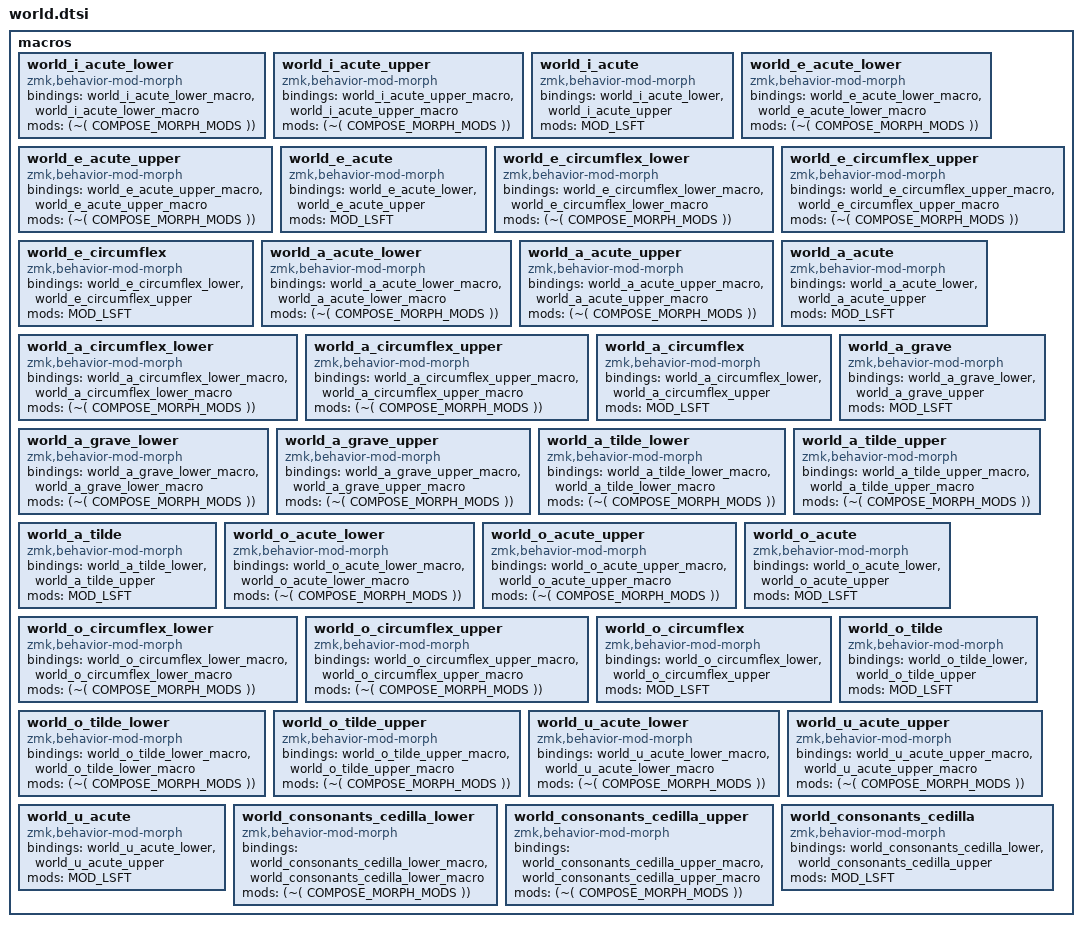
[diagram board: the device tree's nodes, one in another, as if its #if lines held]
macros {

    //////////////////////////////////////////////////////////////////////////
    //
    // World layer - international characters
    //
    //////////////////////////////////////////////////////////////////////////

    //
    // WORLD_USE_COMPOSE uses OS-native Compose keycodes instead of Unicode
    // for characters in the "localizing" section of the `world.yaml` file.
    //
    //#define WORLD_USE_COMPOSE

    //
    // UNICODE_TAP_DELAY defines how long the macro waits (milliseconds)
    // between keystrokes while inputting the Unicode codepoint shortcut.
    //
    #ifndef UNICODE_TAP_DELAY
    #define UNICODE_TAP_DELAY 1
    #endif

    //
    // UNICODE_SEQ_DELAY defines how long the macro waits (milliseconds)
    // between emitting Unicode codepoints in multi-codepoint characters.
    //
    #ifndef UNICODE_SEQ_DELAY
    #define UNICODE_SEQ_DELAY 10
    #endif

    #define UNICODE(name, ...) \
        ZMK_MACRO(name, \
            wait-ms = <UNICODE_TAP_DELAY>; \
            tap-ms = <UNICODE_TAP_DELAY>; \
            bindings = __VA_ARGS__; \
        )

    //
    // UNICODE_SEQ_LINUX() specifies how Unicode hexadecimal codepoint
    // keystrokes are transformed into Unicode characters under Linux.
    //
    #ifndef UNICODE_SEQ_LINUX
    #define UNICODE_SEQ_LINUX(keystrokes) \
        <&macro_tap &kp LC(LS(U)) keystrokes &kp ENTER>
    #endif

    //
    // UNICODE_SEQ_MACOS() specifies how Unicode hexadecimal codepoint
    // keystrokes are transformed into Unicode characters under macOS.
    //
    #ifndef UNICODE_SEQ_MACOS
    #define UNICODE_SEQ_MACOS(keystrokes) \
        <&macro_press &kp LALT> ,\
        <&macro_tap keystrokes> ,\
        <&macro_release &kp LALT>
    #endif

    //
    // UNICODE_SEQ_WINDOWS() specifies how Unicode hexadecimal codepoint
    // keystrokes are transformed into Unicode characters under Windows.
    //
    // If you've configured WinCompose to use a different trigger hotkey,
    // such as F13 instead of the default RA(U) shortcut, simply override
    // this definition to adapt all UNICODE() function calls accordingly.
    //
    #ifndef UNICODE_SEQ_WINDOWS
    #define UNICODE_SEQ_WINDOWS(keystrokes) \
        <&macro_tap &kp RALT &kp U keystrokes &kp ENTER>
    #endif

    //
    // COMPOSE_KEY_LINUX specifies the keycode for Compose key in Linux,
    // which may be RALT by default but can be reconfigured as follows:
    //
    // $ setxkbmap -option compose:sclk # use ScrollLock as Compose key
    //
    // See xkeyboard-config(7) for possible choices for the Compose key:
    // https://manpages.debian.org/stable/xkb-data/xkeyboard-config.7.en.html#Position_of_Compose_key
    //
    // #define COMPOSE_KEY_LINUX RALT            // compose:ralt
    // #define COMPOSE_KEY_LINUX LGUI            // compose:lwin
    // #define COMPOSE_KEY_LINUX RA(LGUI)        // compose:lwin-altgr
    // #define COMPOSE_KEY_LINUX RGUI            // compose:rwin
    // #define COMPOSE_KEY_LINUX RA(RGUI)        // compose:rwin-altgr
    // #define COMPOSE_KEY_LINUX K_MENU          // compose:menu
    // #define COMPOSE_KEY_LINUX RA(K_MENU)      // compose:menu-altgr
    // #define COMPOSE_KEY_LINUX LCTL            // compose:lctrl
    // #define COMPOSE_KEY_LINUX RA(LCTL)        // compose:lctrl-altgr
    // #define COMPOSE_KEY_LINUX RCTL            // compose:rctrl
    // #define COMPOSE_KEY_LINUX RA(RCTL)        // compose:rctrl-altgr
    // #define COMPOSE_KEY_LINUX CAPS            // compose:caps
    // #define COMPOSE_KEY_LINUX RA(CAPS)        // compose:caps-altgr
    // #define COMPOSE_KEY_LINUX NON_US_BSLH     // compose:102
    // #define COMPOSE_KEY_LINUX RA(NON_US_BSLH) // compose:102-altgr
    // #define COMPOSE_KEY_LINUX PAUSE_BREAK     // compose:paus
    // #define COMPOSE_KEY_LINUX PSCRN           // compose:prsc
    // #define COMPOSE_KEY_LINUX SLCK            // compose:sclk
    //
    #ifndef COMPOSE_KEY_LINUX
    #define COMPOSE_KEY_LINUX RALT
    #endif

    //
    // COMPOSE_SEQ_LINUX() prefixes keystrokes with the Linux Compose key.
    //
    #ifndef COMPOSE_SEQ_LINUX
    #define COMPOSE_SEQ_LINUX(keystrokes) \
        <&macro_tap &kp COMPOSE_KEY_LINUX keystrokes>
    #endif

    //
    // COMPOSE_SEQ_MACOS() formats keystrokes for macOS character entry.
    //
    #ifndef COMPOSE_SEQ_MACOS
    #define COMPOSE_SEQ_MACOS(keystrokes) \
        <&macro_tap keystrokes>
    #endif

    //
    // COMPOSE_SEQ_WINDOWS() wraps keystrokes in Windows AltCode sequence.
    //
    #ifndef COMPOSE_SEQ_WINDOWS
    #define COMPOSE_SEQ_WINDOWS(keystrokes) \
        <&macro_press &kp LALT>, \
        <&macro_tap keystrokes>, \
        <&macro_release &kp LALT>
    #endif
    #if OPERATING_SYSTEM == 'L'
        #define UNICODE_MORPH_MODS (MOD_LCTL|MOD_LSFT)
    #elif OPERATING_SYSTEM == 'M'
        #define UNICODE_MORPH_MODS MOD_LALT
    #elif OPERATING_SYSTEM == 'W'
        #define UNICODE_MORPH_MODS MOD_RALT
    #endif
    #if OPERATING_SYSTEM == 'L'
        // $ grep "compose:" /usr/share/X11/xkb/rules/base.lst
        // compose:ralt         Right Alt
        #if COMPOSE_KEY_LINUX == RALT
            #define COMPOSE_MORPH_MODS MOD_RALT
        // compose:lwin         Left Win
        #elif COMPOSE_KEY_LINUX == LGUI
            #define COMPOSE_MORPH_MODS MOD_LGUI
        // compose:lwin-altgr   3rd level of Left Win
        #elif COMPOSE_KEY_LINUX == RA(LGUI)
            #define COMPOSE_MORPH_MODS (MOD_LGUI|MOD_RALT)
        // compose:rwin         Right Win
        #elif COMPOSE_KEY_LINUX == RGUI
            #define COMPOSE_MORPH_MODS MOD_RGUI
        // compose:rwin-altgr   3rd level of Right Win
        #elif COMPOSE_KEY_LINUX == RA(RGUI)
            #define COMPOSE_MORPH_MODS (MOD_RGUI|MOD_RALT)
        // compose:menu         Menu
        // compose:menu-altgr   3rd level of Menu
        #elif COMPOSE_KEY_LINUX == RA(K_MENU)
            #define COMPOSE_MORPH_MODS MOD_RALT
        // compose:lctrl        Left Ctrl
        #elif COMPOSE_KEY_LINUX == LCTL
            #define COMPOSE_MORPH_MODS MOD_LCTL
        // compose:lctrl-altgr  3rd level of Left Ctrl
        #elif COMPOSE_KEY_LINUX == RA(LCTL)
            #define COMPOSE_MORPH_MODS (MOD_LCTL|MOD_RALT)
        // compose:rctrl        Right Ctrl
        #elif COMPOSE_KEY_LINUX == RCTL
            #define COMPOSE_MORPH_MODS MOD_RCTL
        // compose:rctrl-altgr  3rd level of Right Ctrl
        #elif COMPOSE_KEY_LINUX == RA(RCTL)
            #define COMPOSE_MORPH_MODS (MOD_RCTL|MOD_RALT)
        // compose:caps         Caps Lock
        // compose:caps-altgr   3rd level of Caps Lock
        #elif COMPOSE_KEY_LINUX == RA(CAPS)
            #define COMPOSE_MORPH_MODS MOD_RALT
        // compose:102          The "&lt; &gt;" key
        // compose:102-altgr    3rd level of the "&lt; &gt;" key
        #elif COMPOSE_KEY_LINUX == RA(NON_US_BSLH)
            #define COMPOSE_MORPH_MODS MOD_RALT
        // compose:paus         Pause
        // compose:prsc         PrtSc
        // compose:sclk         Scroll Lock
        #else
            #define COMPOSE_MORPH_MODS 0
        #endif
    #elif OPERATING_SYSTEM == 'M'
        #define COMPOSE_MORPH_MODS 0
    #elif OPERATING_SYSTEM == 'W'
        #define COMPOSE_MORPH_MODS MOD_LALT
    #endif


    //
    // characters
    //
    UNICODE(world_i_acute_lower_macro, /* í */
      #if OPERATING_SYSTEM == 'L'
        #ifdef WORLD_USE_COMPOSE
        #define WORLD_USE_COMPOSE_FOR_world_i_acute_lower
        COMPOSE_SEQ_LINUX(&kp SQT &kp I)
        #else
        UNICODE_SEQ_LINUX(&kp E &kp D)
        #endif
      #elif OPERATING_SYSTEM == 'M'
        #ifdef WORLD_USE_COMPOSE
        #define WORLD_USE_COMPOSE_FOR_world_i_acute_lower
        COMPOSE_SEQ_MACOS(&kp LA(E) &kp I)
        #else
        UNICODE_SEQ_MACOS(&kp N0 &kp N0 &kp E &kp D)
        #endif
      #elif OPERATING_SYSTEM == 'W'
        #ifdef WORLD_USE_COMPOSE
        #define WORLD_USE_COMPOSE_FOR_world_i_acute_lower
        COMPOSE_SEQ_WINDOWS(&kp KP_N0 &kp KP_N2 &kp KP_N3 &kp KP_N7)
        #else
        UNICODE_SEQ_WINDOWS(&kp N0 &kp E &kp D)
        #endif
      #endif
    )
    world_i_acute_lower: world_i_acute_lower {
        compatible = "zmk,behavior-mod-morph";
        #binding-cells = <0>;
        bindings = <&world_i_acute_lower_macro>, <&world_i_acute_lower_macro>;
        mods = <(~(
#ifdef WORLD_USE_COMPOSE_FOR_world_i_acute_lower
COMPOSE_MORPH_MODS
#else
UNICODE_MORPH_MODS
#endif
))>;
    };
    UNICODE(world_i_acute_upper_macro, /* Í */
      #if OPERATING_SYSTEM == 'L'
        #ifdef WORLD_USE_COMPOSE
        #define WORLD_USE_COMPOSE_FOR_world_i_acute_upper
        COMPOSE_SEQ_LINUX(&kp SQT &kp LS(I))
        #else
        UNICODE_SEQ_LINUX(&kp C &kp D)
        #endif
      #elif OPERATING_SYSTEM == 'M'
        #ifdef WORLD_USE_COMPOSE
        #define WORLD_USE_COMPOSE_FOR_world_i_acute_upper
        COMPOSE_SEQ_MACOS(&kp LA(E) &kp LS(I))
        #else
        UNICODE_SEQ_MACOS(&kp N0 &kp N0 &kp C &kp D)
        #endif
      #elif OPERATING_SYSTEM == 'W'
        #ifdef WORLD_USE_COMPOSE
        #define WORLD_USE_COMPOSE_FOR_world_i_acute_upper
        COMPOSE_SEQ_WINDOWS(&kp KP_N0 &kp KP_N2 &kp KP_N0 &kp KP_N5)
        #else
        UNICODE_SEQ_WINDOWS(&kp N0 &kp C &kp D)
        #endif
      #endif
    )
    world_i_acute_upper: world_i_acute_upper {
        compatible = "zmk,behavior-mod-morph";
        #binding-cells = <0>;
        bindings = <&world_i_acute_upper_macro>, <&world_i_acute_upper_macro>;
        mods = <(~(
#ifdef WORLD_USE_COMPOSE_FOR_world_i_acute_upper
COMPOSE_MORPH_MODS
#else
UNICODE_MORPH_MODS
#endif
))>;
    };
    world_i_acute: world_i_acute {
        compatible = "zmk,behavior-mod-morph";
        #binding-cells = <0>;
        bindings = <&world_i_acute_lower>, <&world_i_acute_upper>;
        mods = <MOD_LSFT>;
    };
    UNICODE(world_e_acute_lower_macro, /* é */
      #if OPERATING_SYSTEM == 'L'
        #ifdef WORLD_USE_COMPOSE
        #define WORLD_USE_COMPOSE_FOR_world_e_acute_lower
        COMPOSE_SEQ_LINUX(&kp SQT &kp E)
        #else
        UNICODE_SEQ_LINUX(&kp E &kp N9)
        #endif
      #elif OPERATING_SYSTEM == 'M'
        #ifdef WORLD_USE_COMPOSE
        #define WORLD_USE_COMPOSE_FOR_world_e_acute_lower
        COMPOSE_SEQ_MACOS(&kp LA(E) &kp E)
        #else
        UNICODE_SEQ_MACOS(&kp N0 &kp N0 &kp E &kp N9)
        #endif
      #elif OPERATING_SYSTEM == 'W'
        #ifdef WORLD_USE_COMPOSE
        #define WORLD_USE_COMPOSE_FOR_world_e_acute_lower
        COMPOSE_SEQ_WINDOWS(&kp KP_N0 &kp KP_N2 &kp KP_N3 &kp KP_N3)
        #else
        UNICODE_SEQ_WINDOWS(&kp N0 &kp E &kp N9)
        #endif
      #endif
    )
    world_e_acute_lower: world_e_acute_lower {
        compatible = "zmk,behavior-mod-morph";
        #binding-cells = <0>;
        bindings = <&world_e_acute_lower_macro>, <&world_e_acute_lower_macro>;
        mods = <(~(
#ifdef WORLD_USE_COMPOSE_FOR_world_e_acute_lower
COMPOSE_MORPH_MODS
#else
UNICODE_MORPH_MODS
#endif
))>;
    };
    UNICODE(world_e_acute_upper_macro, /* É */
      #if OPERATING_SYSTEM == 'L'
        #ifdef WORLD_USE_COMPOSE
        #define WORLD_USE_COMPOSE_FOR_world_e_acute_upper
        COMPOSE_SEQ_LINUX(&kp SQT &kp LS(E))
        #else
        UNICODE_SEQ_LINUX(&kp C &kp N9)
        #endif
      #elif OPERATING_SYSTEM == 'M'
        #ifdef WORLD_USE_COMPOSE
        #define WORLD_USE_COMPOSE_FOR_world_e_acute_upper
        COMPOSE_SEQ_MACOS(&kp LA(E) &kp LS(E))
        #else
        UNICODE_SEQ_MACOS(&kp N0 &kp N0 &kp C &kp N9)
        #endif
      #elif OPERATING_SYSTEM == 'W'
        #ifdef WORLD_USE_COMPOSE
        #define WORLD_USE_COMPOSE_FOR_world_e_acute_upper
        COMPOSE_SEQ_WINDOWS(&kp KP_N0 &kp KP_N2 &kp KP_N0 &kp KP_N1)
        #else
        UNICODE_SEQ_WINDOWS(&kp N0 &kp C &kp N9)
        #endif
      #endif
    )
    world_e_acute_upper: world_e_acute_upper {
        compatible = "zmk,behavior-mod-morph";
        #binding-cells = <0>;
        bindings = <&world_e_acute_upper_macro>, <&world_e_acute_upper_macro>;
        mods = <(~(
#ifdef WORLD_USE_COMPOSE_FOR_world_e_acute_upper
COMPOSE_MORPH_MODS
#else
UNICODE_MORPH_MODS
#endif
))>;
    };
    world_e_acute: world_e_acute {
        compatible = "zmk,behavior-mod-morph";
        #binding-cells = <0>;
        bindings = <&world_e_acute_lower>, <&world_e_acute_upper>;
        mods = <MOD_LSFT>;
    };
    UNICODE(world_e_circumflex_lower_macro, /* ê */
      #if OPERATING_SYSTEM == 'L'
        #ifdef WORLD_USE_COMPOSE
        #define WORLD_USE_COMPOSE_FOR_world_e_circumflex_lower
        COMPOSE_SEQ_LINUX(&kp CARET &kp E)
        #else
        UNICODE_SEQ_LINUX(&kp E &kp A)
        #endif
      #elif OPERATING_SYSTEM == 'M'
        #ifdef WORLD_USE_COMPOSE
        #define WORLD_USE_COMPOSE_FOR_world_e_circumflex_lower
        COMPOSE_SEQ_MACOS(&kp LA(I) &kp E)
        #else
        UNICODE_SEQ_MACOS(&kp N0 &kp N0 &kp E &kp A)
        #endif
      #elif OPERATING_SYSTEM == 'W'
        #ifdef WORLD_USE_COMPOSE
        #define WORLD_USE_COMPOSE_FOR_world_e_circumflex_lower
        COMPOSE_SEQ_WINDOWS(&kp KP_N0 &kp KP_N2 &kp KP_N3 &kp KP_N4)
        #else
        UNICODE_SEQ_WINDOWS(&kp N0 &kp E &kp A)
        #endif
      #endif
    )
    world_e_circumflex_lower: world_e_circumflex_lower {
        compatible = "zmk,behavior-mod-morph";
        #binding-cells = <0>;
        bindings = <&world_e_circumflex_lower_macro>, <&world_e_circumflex_lower_macro>;
        mods = <(~(
#ifdef WORLD_USE_COMPOSE_FOR_world_e_circumflex_lower
COMPOSE_MORPH_MODS
#else
UNICODE_MORPH_MODS
#endif
))>;
    };
    UNICODE(world_e_circumflex_upper_macro, /* Ê */
      #if OPERATING_SYSTEM == 'L'
        #ifdef WORLD_USE_COMPOSE
        #define WORLD_USE_COMPOSE_FOR_world_e_circumflex_upper
        COMPOSE_SEQ_LINUX(&kp CARET &kp LS(E))
        #else
        UNICODE_SEQ_LINUX(&kp C &kp A)
        #endif
      #elif OPERATING_SYSTEM == 'M'
        #ifdef WORLD_USE_COMPOSE
        #define WORLD_USE_COMPOSE_FOR_world_e_circumflex_upper
        COMPOSE_SEQ_MACOS(&kp LA(I) &kp LS(E))
        #else
        UNICODE_SEQ_MACOS(&kp N0 &kp N0 &kp C &kp A)
        #endif
      #elif OPERATING_SYSTEM == 'W'
        #ifdef WORLD_USE_COMPOSE
        #define WORLD_USE_COMPOSE_FOR_world_e_circumflex_upper
        COMPOSE_SEQ_WINDOWS(&kp KP_N0 &kp KP_N2 &kp KP_N0 &kp KP_N2)
        #else
        UNICODE_SEQ_WINDOWS(&kp N0 &kp C &kp A)
        #endif
      #endif
    )
    world_e_circumflex_upper: world_e_circumflex_upper {
        compatible = "zmk,behavior-mod-morph";
        #binding-cells = <0>;
        bindings = <&world_e_circumflex_upper_macro>, <&world_e_circumflex_upper_macro>;
        mods = <(~(
#ifdef WORLD_USE_COMPOSE_FOR_world_e_circumflex_upper
COMPOSE_MORPH_MODS
#else
UNICODE_MORPH_MODS
#endif
))>;
    };
    world_e_circumflex: world_e_circumflex {
        compatible = "zmk,behavior-mod-morph";
        #binding-cells = <0>;
        bindings = <&world_e_circumflex_lower>, <&world_e_circumflex_upper>;
        mods = <MOD_LSFT>;
    };
    UNICODE(world_a_acute_lower_macro, /* á */
      #if OPERATING_SYSTEM == 'L'
        #ifdef WORLD_USE_COMPOSE
        #define WORLD_USE_COMPOSE_FOR_world_a_acute_lower
        COMPOSE_SEQ_LINUX(&kp SQT &kp A)
        #else
        UNICODE_SEQ_LINUX(&kp E &kp N1)
        #endif
      #elif OPERATING_SYSTEM == 'M'
        #ifdef WORLD_USE_COMPOSE
        #define WORLD_USE_COMPOSE_FOR_world_a_acute_lower
        COMPOSE_SEQ_MACOS(&kp LA(E) &kp A)
        #else
        UNICODE_SEQ_MACOS(&kp N0 &kp N0 &kp E &kp N1)
        #endif
      #elif OPERATING_SYSTEM == 'W'
        #ifdef WORLD_USE_COMPOSE
        #define WORLD_USE_COMPOSE_FOR_world_a_acute_lower
        COMPOSE_SEQ_WINDOWS(&kp KP_N0 &kp KP_N2 &kp KP_N2 &kp KP_N5)
        #else
        UNICODE_SEQ_WINDOWS(&kp N0 &kp E &kp N1)
        #endif
      #endif
    )
    world_a_acute_lower: world_a_acute_lower {
        compatible = "zmk,behavior-mod-morph";
        #binding-cells = <0>;
        bindings = <&world_a_acute_lower_macro>, <&world_a_acute_lower_macro>;
        mods = <(~(
#ifdef WORLD_USE_COMPOSE_FOR_world_a_acute_lower
COMPOSE_MORPH_MODS
#else
UNICODE_MORPH_MODS
#endif
))>;
    };
    UNICODE(world_a_acute_upper_macro, /* Á */
      #if OPERATING_SYSTEM == 'L'
        #ifdef WORLD_USE_COMPOSE
        #define WORLD_USE_COMPOSE_FOR_world_a_acute_upper
        COMPOSE_SEQ_LINUX(&kp SQT &kp LS(A))
        #else
        UNICODE_SEQ_LINUX(&kp C &kp N1)
        #endif
      #elif OPERATING_SYSTEM == 'M'
        #ifdef WORLD_USE_COMPOSE
        #define WORLD_USE_COMPOSE_FOR_world_a_acute_upper
        COMPOSE_SEQ_MACOS(&kp LA(E) &kp LS(A))
        #else
        UNICODE_SEQ_MACOS(&kp N0 &kp N0 &kp C &kp N1)
        #endif
      #elif OPERATING_SYSTEM == 'W'
        #ifdef WORLD_USE_COMPOSE
        #define WORLD_USE_COMPOSE_FOR_world_a_acute_upper
        COMPOSE_SEQ_WINDOWS(&kp KP_N0 &kp KP_N1 &kp KP_N9 &kp KP_N3)
        #else
        UNICODE_SEQ_WINDOWS(&kp N0 &kp C &kp N1)
        #endif
      #endif
    )
    world_a_acute_upper: world_a_acute_upper {
        compatible = "zmk,behavior-mod-morph";
        #binding-cells = <0>;
        bindings = <&world_a_acute_upper_macro>, <&world_a_acute_upper_macro>;
        mods = <(~(
#ifdef WORLD_USE_COMPOSE_FOR_world_a_acute_upper
COMPOSE_MORPH_MODS
#else
UNICODE_MORPH_MODS
#endif
))>;
    };
    world_a_acute: world_a_acute {
        compatible = "zmk,behavior-mod-morph";
        #binding-cells = <0>;
        bindings = <&world_a_acute_lower>, <&world_a_acute_upper>;
        mods = <MOD_LSFT>;
    };
    UNICODE(world_a_circumflex_lower_macro, /* â */
      #if OPERATING_SYSTEM == 'L'
        #ifdef WORLD_USE_COMPOSE
        #define WORLD_USE_COMPOSE_FOR_world_a_circumflex_lower
        COMPOSE_SEQ_LINUX(&kp CARET &kp A)
        #else
        UNICODE_SEQ_LINUX(&kp E &kp N2)
        #endif
      #elif OPERATING_SYSTEM == 'M'
        #ifdef WORLD_USE_COMPOSE
        #define WORLD_USE_COMPOSE_FOR_world_a_circumflex_lower
        COMPOSE_SEQ_MACOS(&kp LA(I) &kp A)
        #else
        UNICODE_SEQ_MACOS(&kp N0 &kp N0 &kp E &kp N2)
        #endif
      #elif OPERATING_SYSTEM == 'W'
        #ifdef WORLD_USE_COMPOSE
        #define WORLD_USE_COMPOSE_FOR_world_a_circumflex_lower
        COMPOSE_SEQ_WINDOWS(&kp KP_N0 &kp KP_N2 &kp KP_N2 &kp KP_N6)
        #else
        UNICODE_SEQ_WINDOWS(&kp N0 &kp E &kp N2)
        #endif
      #endif
    )
    world_a_circumflex_lower: world_a_circumflex_lower {
        compatible = "zmk,behavior-mod-morph";
        #binding-cells = <0>;
        bindings = <&world_a_circumflex_lower_macro>, <&world_a_circumflex_lower_macro>;
        mods = <(~(
#ifdef WORLD_USE_COMPOSE_FOR_world_a_circumflex_lower
COMPOSE_MORPH_MODS
#else
UNICODE_MORPH_MODS
#endif
))>;
    };
    UNICODE(world_a_circumflex_upper_macro, /* Â */
      #if OPERATING_SYSTEM == 'L'
        #ifdef WORLD_USE_COMPOSE
        #define WORLD_USE_COMPOSE_FOR_world_a_circumflex_upper
        COMPOSE_SEQ_LINUX(&kp CARET &kp LS(A))
        #else
        UNICODE_SEQ_LINUX(&kp C &kp N2)
        #endif
      #elif OPERATING_SYSTEM == 'M'
        #ifdef WORLD_USE_COMPOSE
        #define WORLD_USE_COMPOSE_FOR_world_a_circumflex_upper
        COMPOSE_SEQ_MACOS(&kp LA(I) &kp LS(A))
        #else
        UNICODE_SEQ_MACOS(&kp N0 &kp N0 &kp C &kp N2)
        #endif
      #elif OPERATING_SYSTEM == 'W'
        #ifdef WORLD_USE_COMPOSE
        #define WORLD_USE_COMPOSE_FOR_world_a_circumflex_upper
        COMPOSE_SEQ_WINDOWS(&kp KP_N0 &kp KP_N1 &kp KP_N9 &kp KP_N4)
        #else
        UNICODE_SEQ_WINDOWS(&kp N0 &kp C &kp N2)
        #endif
      #endif
    )
    world_a_circumflex_upper: world_a_circumflex_upper {
        compatible = "zmk,behavior-mod-morph";
        #binding-cells = <0>;
        bindings = <&world_a_circumflex_upper_macro>, <&world_a_circumflex_upper_macro>;
        mods = <(~(
#ifdef WORLD_USE_COMPOSE_FOR_world_a_circumflex_upper
COMPOSE_MORPH_MODS
#else
UNICODE_MORPH_MODS
#endif
))>;
    };
    world_a_circumflex: world_a_circumflex {
        compatible = "zmk,behavior-mod-morph";
        #binding-cells = <0>;
        bindings = <&world_a_circumflex_lower>, <&world_a_circumflex_upper>;
        mods = <MOD_LSFT>;
    };
    UNICODE(world_a_grave_lower_macro, /* à */
      #if OPERATING_SYSTEM == 'L'
        #ifdef WORLD_USE_COMPOSE
        #define WORLD_USE_COMPOSE_FOR_world_a_grave_lower
        COMPOSE_SEQ_LINUX(&kp GRAVE &kp A)
        #else
        UNICODE_SEQ_LINUX(&kp E &kp N0)
        #endif
      #elif OPERATING_SYSTEM == 'M'
        #ifdef WORLD_USE_COMPOSE
        #define WORLD_USE_COMPOSE_FOR_world_a_grave_lower
        COMPOSE_SEQ_MACOS(&kp LA(GRAVE) &kp A)
        #else
        UNICODE_SEQ_MACOS(&kp N0 &kp N0 &kp E &kp N0)
        #endif
      #elif OPERATING_SYSTEM == 'W'
        #ifdef WORLD_USE_COMPOSE
        #define WORLD_USE_COMPOSE_FOR_world_a_grave_lower
        COMPOSE_SEQ_WINDOWS(&kp KP_N0 &kp KP_N2 &kp KP_N2 &kp KP_N4)
        #else
        UNICODE_SEQ_WINDOWS(&kp N0 &kp E &kp N0)
        #endif
      #endif
    )
    world_a_grave_lower: world_a_grave_lower {
        compatible = "zmk,behavior-mod-morph";
        #binding-cells = <0>;
        bindings = <&world_a_grave_lower_macro>, <&world_a_grave_lower_macro>;
        mods = <(~(
#ifdef WORLD_USE_COMPOSE_FOR_world_a_grave_lower
COMPOSE_MORPH_MODS
#else
UNICODE_MORPH_MODS
#endif
))>;
    };
    UNICODE(world_a_grave_upper_macro, /* À */
      #if OPERATING_SYSTEM == 'L'
        #ifdef WORLD_USE_COMPOSE
        #define WORLD_USE_COMPOSE_FOR_world_a_grave_upper
        COMPOSE_SEQ_LINUX(&kp GRAVE &kp LS(A))
        #else
        UNICODE_SEQ_LINUX(&kp C &kp N0)
        #endif
      #elif OPERATING_SYSTEM == 'M'
        #ifdef WORLD_USE_COMPOSE
        #define WORLD_USE_COMPOSE_FOR_world_a_grave_upper
        COMPOSE_SEQ_MACOS(&kp LA(GRAVE) &kp LS(A))
        #else
        UNICODE_SEQ_MACOS(&kp N0 &kp N0 &kp C &kp N0)
        #endif
      #elif OPERATING_SYSTEM == 'W'
        #ifdef WORLD_USE_COMPOSE
        #define WORLD_USE_COMPOSE_FOR_world_a_grave_upper
        COMPOSE_SEQ_WINDOWS(&kp KP_N0 &kp KP_N1 &kp KP_N9 &kp KP_N2)
        #else
        UNICODE_SEQ_WINDOWS(&kp N0 &kp C &kp N0)
        #endif
      #endif
    )
    world_a_grave_upper: world_a_grave_upper {
        compatible = "zmk,behavior-mod-morph";
        #binding-cells = <0>;
        bindings = <&world_a_grave_upper_macro>, <&world_a_grave_upper_macro>;
        mods = <(~(
#ifdef WORLD_USE_COMPOSE_FOR_world_a_grave_upper
COMPOSE_MORPH_MODS
#else
UNICODE_MORPH_MODS
#endif
))>;
    };
    world_a_grave: world_a_grave {
        compatible = "zmk,behavior-mod-morph";
        #binding-cells = <0>;
        bindings = <&world_a_grave_lower>, <&world_a_grave_upper>;
        mods = <MOD_LSFT>;
    };
    UNICODE(world_a_tilde_lower_macro, /* ã */
      #if OPERATING_SYSTEM == 'L'
        #ifdef WORLD_USE_COMPOSE
        #define WORLD_USE_COMPOSE_FOR_world_a_tilde_lower
        COMPOSE_SEQ_LINUX(&kp TILDE &kp A)
        #else
        UNICODE_SEQ_LINUX(&kp E &kp N3)
        #endif
      #elif OPERATING_SYSTEM == 'M'
        #ifdef WORLD_USE_COMPOSE
        #define WORLD_USE_COMPOSE_FOR_world_a_tilde_lower
        COMPOSE_SEQ_MACOS(&kp LA(N) &kp A)
        #else
        UNICODE_SEQ_MACOS(&kp N0 &kp N0 &kp E &kp N3)
        #endif
      #elif OPERATING_SYSTEM == 'W'
        #ifdef WORLD_USE_COMPOSE
        #define WORLD_USE_COMPOSE_FOR_world_a_tilde_lower
        COMPOSE_SEQ_WINDOWS(&kp KP_N0 &kp KP_N2 &kp KP_N2 &kp KP_N7)
        #else
        UNICODE_SEQ_WINDOWS(&kp N0 &kp E &kp N3)
        #endif
      #endif
    )
    world_a_tilde_lower: world_a_tilde_lower {
        compatible = "zmk,behavior-mod-morph";
        #binding-cells = <0>;
        bindings = <&world_a_tilde_lower_macro>, <&world_a_tilde_lower_macro>;
        mods = <(~(
#ifdef WORLD_USE_COMPOSE_FOR_world_a_tilde_lower
COMPOSE_MORPH_MODS
#else
UNICODE_MORPH_MODS
#endif
))>;
    };
    UNICODE(world_a_tilde_upper_macro, /* Ã */
      #if OPERATING_SYSTEM == 'L'
        #ifdef WORLD_USE_COMPOSE
        #define WORLD_USE_COMPOSE_FOR_world_a_tilde_upper
        COMPOSE_SEQ_LINUX(&kp TILDE &kp LS(A))
        #else
        UNICODE_SEQ_LINUX(&kp C &kp N3)
        #endif
      #elif OPERATING_SYSTEM == 'M'
        #ifdef WORLD_USE_COMPOSE
        #define WORLD_USE_COMPOSE_FOR_world_a_tilde_upper
        COMPOSE_SEQ_MACOS(&kp LA(N) &kp LS(A))
        #else
        UNICODE_SEQ_MACOS(&kp N0 &kp N0 &kp C &kp N3)
        #endif
      #elif OPERATING_SYSTEM == 'W'
        #ifdef WORLD_USE_COMPOSE
        #define WORLD_USE_COMPOSE_FOR_world_a_tilde_upper
        COMPOSE_SEQ_WINDOWS(&kp KP_N0 &kp KP_N1 &kp KP_N9 &kp KP_N5)
        #else
        UNICODE_SEQ_WINDOWS(&kp N0 &kp C &kp N3)
        #endif
      #endif
    )
    world_a_tilde_upper: world_a_tilde_upper {
        compatible = "zmk,behavior-mod-morph";
        #binding-cells = <0>;
        bindings = <&world_a_tilde_upper_macro>, <&world_a_tilde_upper_macro>;
        mods = <(~(
#ifdef WORLD_USE_COMPOSE_FOR_world_a_tilde_upper
COMPOSE_MORPH_MODS
#else
UNICODE_MORPH_MODS
#endif
))>;
    };
    world_a_tilde: world_a_tilde {
        compatible = "zmk,behavior-mod-morph";
        #binding-cells = <0>;
        bindings = <&world_a_tilde_lower>, <&world_a_tilde_upper>;
        mods = <MOD_LSFT>;
    };
    UNICODE(world_o_acute_lower_macro, /* ó */
      #if OPERATING_SYSTEM == 'L'
        #ifdef WORLD_USE_COMPOSE
        #define WORLD_USE_COMPOSE_FOR_world_o_acute_lower
        COMPOSE_SEQ_LINUX(&kp SQT &kp O)
        #else
        UNICODE_SEQ_LINUX(&kp F &kp N3)
        #endif
      #elif OPERATING_SYSTEM == 'M'
        #ifdef WORLD_USE_COMPOSE
        #define WORLD_USE_COMPOSE_FOR_world_o_acute_lower
        COMPOSE_SEQ_MACOS(&kp LA(E) &kp O)
        #else
        UNICODE_SEQ_MACOS(&kp N0 &kp N0 &kp F &kp N3)
        #endif
      #elif OPERATING_SYSTEM == 'W'
        #ifdef WORLD_USE_COMPOSE
        #define WORLD_USE_COMPOSE_FOR_world_o_acute_lower
        COMPOSE_SEQ_WINDOWS(&kp KP_N0 &kp KP_N2 &kp KP_N4 &kp KP_N3)
        #else
        UNICODE_SEQ_WINDOWS(&kp N0 &kp F &kp N3)
        #endif
      #endif
    )
    world_o_acute_lower: world_o_acute_lower {
        compatible = "zmk,behavior-mod-morph";
        #binding-cells = <0>;
        bindings = <&world_o_acute_lower_macro>, <&world_o_acute_lower_macro>;
        mods = <(~(
#ifdef WORLD_USE_COMPOSE_FOR_world_o_acute_lower
COMPOSE_MORPH_MODS
#else
UNICODE_MORPH_MODS
#endif
))>;
    };
    UNICODE(world_o_acute_upper_macro, /* Ó */
      #if OPERATING_SYSTEM == 'L'
        #ifdef WORLD_USE_COMPOSE
        #define WORLD_USE_COMPOSE_FOR_world_o_acute_upper
        COMPOSE_SEQ_LINUX(&kp SQT &kp LS(O))
        #else
        UNICODE_SEQ_LINUX(&kp D &kp N3)
        #endif
      #elif OPERATING_SYSTEM == 'M'
        #ifdef WORLD_USE_COMPOSE
        #define WORLD_USE_COMPOSE_FOR_world_o_acute_upper
        COMPOSE_SEQ_MACOS(&kp LA(E) &kp LS(O))
        #else
        UNICODE_SEQ_MACOS(&kp N0 &kp N0 &kp D &kp N3)
        #endif
      #elif OPERATING_SYSTEM == 'W'
        #ifdef WORLD_USE_COMPOSE
        #define WORLD_USE_COMPOSE_FOR_world_o_acute_upper
        COMPOSE_SEQ_WINDOWS(&kp KP_N0 &kp KP_N2 &kp KP_N1 &kp KP_N1)
        #else
        UNICODE_SEQ_WINDOWS(&kp N0 &kp D &kp N3)
        #endif
      #endif
    )
    world_o_acute_upper: world_o_acute_upper {
        compatible = "zmk,behavior-mod-morph";
        #binding-cells = <0>;
        bindings = <&world_o_acute_upper_macro>, <&world_o_acute_upper_macro>;
        mods = <(~(
#ifdef WORLD_USE_COMPOSE_FOR_world_o_acute_upper
COMPOSE_MORPH_MODS
#else
UNICODE_MORPH_MODS
#endif
))>;
    };
    world_o_acute: world_o_acute {
        compatible = "zmk,behavior-mod-morph";
        #binding-cells = <0>;
        bindings = <&world_o_acute_lower>, <&world_o_acute_upper>;
        mods = <MOD_LSFT>;
    };
    UNICODE(world_o_circumflex_lower_macro, /* ô */
      #if OPERATING_SYSTEM == 'L'
        #ifdef WORLD_USE_COMPOSE
        #define WORLD_USE_COMPOSE_FOR_world_o_circumflex_lower
        COMPOSE_SEQ_LINUX(&kp CARET &kp O)
        #else
        UNICODE_SEQ_LINUX(&kp F &kp N4)
        #endif
      #elif OPERATING_SYSTEM == 'M'
        #ifdef WORLD_USE_COMPOSE
        #define WORLD_USE_COMPOSE_FOR_world_o_circumflex_lower
        COMPOSE_SEQ_MACOS(&kp LA(I) &kp O)
        #else
        UNICODE_SEQ_MACOS(&kp N0 &kp N0 &kp F &kp N4)
        #endif
      #elif OPERATING_SYSTEM == 'W'
        #ifdef WORLD_USE_COMPOSE
        #define WORLD_USE_COMPOSE_FOR_world_o_circumflex_lower
        COMPOSE_SEQ_WINDOWS(&kp KP_N0 &kp KP_N2 &kp KP_N4 &kp KP_N4)
        #else
        UNICODE_SEQ_WINDOWS(&kp N0 &kp F &kp N4)
        #endif
      #endif
    )
    world_o_circumflex_lower: world_o_circumflex_lower {
        compatible = "zmk,behavior-mod-morph";
        #binding-cells = <0>;
        bindings = <&world_o_circumflex_lower_macro>, <&world_o_circumflex_lower_macro>;
        mods = <(~(
#ifdef WORLD_USE_COMPOSE_FOR_world_o_circumflex_lower
COMPOSE_MORPH_MODS
#else
UNICODE_MORPH_MODS
#endif
))>;
    };
    UNICODE(world_o_circumflex_upper_macro, /* Ô */
      #if OPERATING_SYSTEM == 'L'
        #ifdef WORLD_USE_COMPOSE
        #define WORLD_USE_COMPOSE_FOR_world_o_circumflex_upper
        COMPOSE_SEQ_LINUX(&kp CARET &kp LS(O))
        #else
        UNICODE_SEQ_LINUX(&kp D &kp N4)
        #endif
      #elif OPERATING_SYSTEM == 'M'
        #ifdef WORLD_USE_COMPOSE
        #define WORLD_USE_COMPOSE_FOR_world_o_circumflex_upper
        COMPOSE_SEQ_MACOS(&kp LA(I) &kp LS(O))
        #else
        UNICODE_SEQ_MACOS(&kp N0 &kp N0 &kp D &kp N4)
        #endif
      #elif OPERATING_SYSTEM == 'W'
        #ifdef WORLD_USE_COMPOSE
        #define WORLD_USE_COMPOSE_FOR_world_o_circumflex_upper
        COMPOSE_SEQ_WINDOWS(&kp KP_N0 &kp KP_N2 &kp KP_N1 &kp KP_N2)
        #else
        UNICODE_SEQ_WINDOWS(&kp N0 &kp D &kp N4)
        #endif
      #endif
    )
    world_o_circumflex_upper: world_o_circumflex_upper {
        compatible = "zmk,behavior-mod-morph";
        #binding-cells = <0>;
        bindings = <&world_o_circumflex_upper_macro>, <&world_o_circumflex_upper_macro>;
        mods = <(~(
#ifdef WORLD_USE_COMPOSE_FOR_world_o_circumflex_upper
COMPOSE_MORPH_MODS
#else
UNICODE_MORPH_MODS
#endif
))>;
    };
    world_o_circumflex: world_o_circumflex {
        compatible = "zmk,behavior-mod-morph";
        #binding-cells = <0>;
        bindings = <&world_o_circumflex_lower>, <&world_o_circumflex_upper>;
        mods = <MOD_LSFT>;
    };
    UNICODE(world_o_tilde_lower_macro, /* õ */
      #if OPERATING_SYSTEM == 'L'
        #ifdef WORLD_USE_COMPOSE
        #define WORLD_USE_COMPOSE_FOR_world_o_tilde_lower
        COMPOSE_SEQ_LINUX(&kp TILDE &kp O)
        #else
        UNICODE_SEQ_LINUX(&kp F &kp N5)
        #endif
      #elif OPERATING_SYSTEM == 'M'
        #ifdef WORLD_USE_COMPOSE
        #define WORLD_USE_COMPOSE_FOR_world_o_tilde_lower
        COMPOSE_SEQ_MACOS(&kp LA(N) &kp O)
        #else
        UNICODE_SEQ_MACOS(&kp N0 &kp N0 &kp F &kp N5)
        #endif
      #elif OPERATING_SYSTEM == 'W'
        #ifdef WORLD_USE_COMPOSE
        #define WORLD_USE_COMPOSE_FOR_world_o_tilde_lower
        COMPOSE_SEQ_WINDOWS(&kp KP_N0 &kp KP_N2 &kp KP_N4 &kp KP_N5)
        #else
        UNICODE_SEQ_WINDOWS(&kp N0 &kp F &kp N5)
        #endif
      #endif
    )
    world_o_tilde_lower: world_o_tilde_lower {
        compatible = "zmk,behavior-mod-morph";
        #binding-cells = <0>;
        bindings = <&world_o_tilde_lower_macro>, <&world_o_tilde_lower_macro>;
        mods = <(~(
#ifdef WORLD_USE_COMPOSE_FOR_world_o_tilde_lower
COMPOSE_MORPH_MODS
#else
UNICODE_MORPH_MODS
#endif
))>;
    };
    UNICODE(world_o_tilde_upper_macro, /* Õ */
      #if OPERATING_SYSTEM == 'L'
        #ifdef WORLD_USE_COMPOSE
        #define WORLD_USE_COMPOSE_FOR_world_o_tilde_upper
        COMPOSE_SEQ_LINUX(&kp TILDE &kp LS(O))
        #else
        UNICODE_SEQ_LINUX(&kp D &kp N5)
        #endif
      #elif OPERATING_SYSTEM == 'M'
        #ifdef WORLD_USE_COMPOSE
        #define WORLD_USE_COMPOSE_FOR_world_o_tilde_upper
        COMPOSE_SEQ_MACOS(&kp LA(N) &kp LS(O))
        #else
        UNICODE_SEQ_MACOS(&kp N0 &kp N0 &kp D &kp N5)
        #endif
      #elif OPERATING_SYSTEM == 'W'
        #ifdef WORLD_USE_COMPOSE
        #define WORLD_USE_COMPOSE_FOR_world_o_tilde_upper
        COMPOSE_SEQ_WINDOWS(&kp KP_N0 &kp KP_N2 &kp KP_N1 &kp KP_N3)
        #else
        UNICODE_SEQ_WINDOWS(&kp N0 &kp D &kp N5)
        #endif
      #endif
    )
    world_o_tilde_upper: world_o_tilde_upper {
        compatible = "zmk,behavior-mod-morph";
        #binding-cells = <0>;
        bindings = <&world_o_tilde_upper_macro>, <&world_o_tilde_upper_macro>;
        mods = <(~(
#ifdef WORLD_USE_COMPOSE_FOR_world_o_tilde_upper
COMPOSE_MORPH_MODS
#else
UNICODE_MORPH_MODS
#endif
))>;
    };
    world_o_tilde: world_o_tilde {
        compatible = "zmk,behavior-mod-morph";
        #binding-cells = <0>;
        bindings = <&world_o_tilde_lower>, <&world_o_tilde_upper>;
        mods = <MOD_LSFT>;
    };
    UNICODE(world_u_acute_lower_macro, /* ú */
      #if OPERATING_SYSTEM == 'L'
        #ifdef WORLD_USE_COMPOSE
        #define WORLD_USE_COMPOSE_FOR_world_u_acute_lower
        COMPOSE_SEQ_LINUX(&kp SQT &kp U)
        #else
        UNICODE_SEQ_LINUX(&kp F &kp A)
        #endif
      #elif OPERATING_SYSTEM == 'M'
        #ifdef WORLD_USE_COMPOSE
        #define WORLD_USE_COMPOSE_FOR_world_u_acute_lower
        COMPOSE_SEQ_MACOS(&kp LA(E) &kp U)
        #else
        UNICODE_SEQ_MACOS(&kp N0 &kp N0 &kp F &kp A)
        #endif
      #elif OPERATING_SYSTEM == 'W'
        #ifdef WORLD_USE_COMPOSE
        #define WORLD_USE_COMPOSE_FOR_world_u_acute_lower
        COMPOSE_SEQ_WINDOWS(&kp KP_N0 &kp KP_N2 &kp KP_N5 &kp KP_N0)
        #else
        UNICODE_SEQ_WINDOWS(&kp N0 &kp F &kp A)
        #endif
      #endif
    )
    world_u_acute_lower: world_u_acute_lower {
        compatible = "zmk,behavior-mod-morph";
        #binding-cells = <0>;
        bindings = <&world_u_acute_lower_macro>, <&world_u_acute_lower_macro>;
        mods = <(~(
#ifdef WORLD_USE_COMPOSE_FOR_world_u_acute_lower
COMPOSE_MORPH_MODS
#else
UNICODE_MORPH_MODS
#endif
))>;
    };
    UNICODE(world_u_acute_upper_macro, /* Ú */
      #if OPERATING_SYSTEM == 'L'
        #ifdef WORLD_USE_COMPOSE
        #define WORLD_USE_COMPOSE_FOR_world_u_acute_upper
        COMPOSE_SEQ_LINUX(&kp SQT &kp LS(U))
        #else
        UNICODE_SEQ_LINUX(&kp D &kp A)
        #endif
      #elif OPERATING_SYSTEM == 'M'
        #ifdef WORLD_USE_COMPOSE
        #define WORLD_USE_COMPOSE_FOR_world_u_acute_upper
        COMPOSE_SEQ_MACOS(&kp LA(E) &kp LS(U))
        #else
        UNICODE_SEQ_MACOS(&kp N0 &kp N0 &kp D &kp A)
        #endif
      #elif OPERATING_SYSTEM == 'W'
        #ifdef WORLD_USE_COMPOSE
        #define WORLD_USE_COMPOSE_FOR_world_u_acute_upper
        COMPOSE_SEQ_WINDOWS(&kp KP_N0 &kp KP_N2 &kp KP_N1 &kp KP_N8)
        #else
        UNICODE_SEQ_WINDOWS(&kp N0 &kp D &kp A)
        #endif
      #endif
    )
    world_u_acute_upper: world_u_acute_upper {
        compatible = "zmk,behavior-mod-morph";
        #binding-cells = <0>;
        bindings = <&world_u_acute_upper_macro>, <&world_u_acute_upper_macro>;
        mods = <(~(
#ifdef WORLD_USE_COMPOSE_FOR_world_u_acute_upper
COMPOSE_MORPH_MODS
#else
UNICODE_MORPH_MODS
#endif
))>;
    };
    world_u_acute: world_u_acute {
        compatible = "zmk,behavior-mod-morph";
        #binding-cells = <0>;
        bindings = <&world_u_acute_lower>, <&world_u_acute_upper>;
        mods = <MOD_LSFT>;
    };
    UNICODE(world_consonants_cedilla_lower_macro, /* ç */
      #if OPERATING_SYSTEM == 'L'
        #ifdef WORLD_USE_COMPOSE
        #define WORLD_USE_COMPOSE_FOR_world_consonants_cedilla_lower
        COMPOSE_SEQ_LINUX(&kp COMMA &kp C)
        #else
        UNICODE_SEQ_LINUX(&kp E &kp N7)
        #endif
      #elif OPERATING_SYSTEM == 'M'
        #ifdef WORLD_USE_COMPOSE
        #define WORLD_USE_COMPOSE_FOR_world_consonants_cedilla_lower
        COMPOSE_SEQ_MACOS(&kp LA(C))
        #else
        UNICODE_SEQ_MACOS(&kp N0 &kp N0 &kp E &kp N7)
        #endif
      #elif OPERATING_SYSTEM == 'W'
        #ifdef WORLD_USE_COMPOSE
        #define WORLD_USE_COMPOSE_FOR_world_consonants_cedilla_lower
        COMPOSE_SEQ_WINDOWS(&kp KP_N0 &kp KP_N2 &kp KP_N3 &kp KP_N1)
        #else
        UNICODE_SEQ_WINDOWS(&kp N0 &kp E &kp N7)
        #endif
      #endif
    )
    world_consonants_cedilla_lower: world_consonants_cedilla_lower {
        compatible = "zmk,behavior-mod-morph";
        #binding-cells = <0>;
        bindings = <&world_consonants_cedilla_lower_macro>, <&world_consonants_cedilla_lower_macro>;
        mods = <(~(
#ifdef WORLD_USE_COMPOSE_FOR_world_consonants_cedilla_lower
COMPOSE_MORPH_MODS
#else
UNICODE_MORPH_MODS
#endif
))>;
    };
    UNICODE(world_consonants_cedilla_upper_macro, /* Ç */
      #if OPERATING_SYSTEM == 'L'
        #ifdef WORLD_USE_COMPOSE
        #define WORLD_USE_COMPOSE_FOR_world_consonants_cedilla_upper
        COMPOSE_SEQ_LINUX(&kp COMMA &kp LS(C))
        #else
        UNICODE_SEQ_LINUX(&kp C &kp N7)
        #endif
      #elif OPERATING_SYSTEM == 'M'
        #ifdef WORLD_USE_COMPOSE
        #define WORLD_USE_COMPOSE_FOR_world_consonants_cedilla_upper
        COMPOSE_SEQ_MACOS(&kp LA(LS(C)))
        #else
        UNICODE_SEQ_MACOS(&kp N0 &kp N0 &kp C &kp N7)
        #endif
      #elif OPERATING_SYSTEM == 'W'
        #ifdef WORLD_USE_COMPOSE
        #define WORLD_USE_COMPOSE_FOR_world_consonants_cedilla_upper
        COMPOSE_SEQ_WINDOWS(&kp KP_N0 &kp KP_N1 &kp KP_N9 &kp KP_N9)
        #else
        UNICODE_SEQ_WINDOWS(&kp N0 &kp C &kp N7)
        #endif
      #endif
    )
    world_consonants_cedilla_upper: world_consonants_cedilla_upper {
        compatible = "zmk,behavior-mod-morph";
        #binding-cells = <0>;
        bindings = <&world_consonants_cedilla_upper_macro>, <&world_consonants_cedilla_upper_macro>;
        mods = <(~(
#ifdef WORLD_USE_COMPOSE_FOR_world_consonants_cedilla_upper
COMPOSE_MORPH_MODS
#else
UNICODE_MORPH_MODS
#endif
))>;
    };
    world_consonants_cedilla: world_consonants_cedilla {
        compatible = "zmk,behavior-mod-morph";
        #binding-cells = <0>;
        bindings = <&world_consonants_cedilla_lower>, <&world_consonants_cedilla_upper>;
        mods = <MOD_LSFT>;
    };

};

